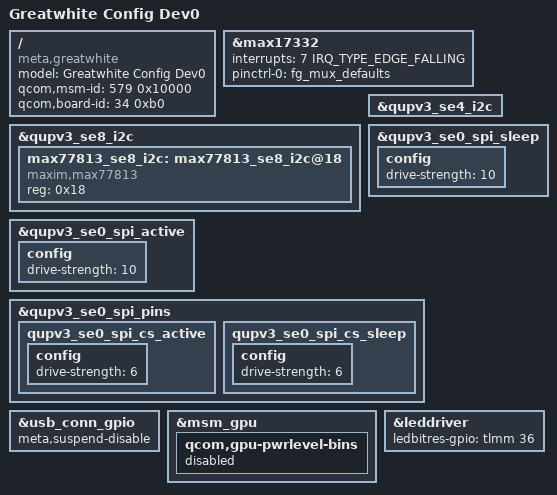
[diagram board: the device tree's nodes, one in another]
/dts-v1/;
/plugin/;

#include "greatwhite.dtsi"
#include "greatwhite-gpios.dtsi"

/ {
	model = "Greatwhite Config Dev0";
	compatible = "meta,greatwhite", "meta,greatwhite-dev0";
	qcom,msm-id = <579 0x10000>;
	qcom,board-id = <34 0xb0>;
};

&max17332 {
	interrupts = <7 IRQ_TYPE_EDGE_FALLING>;
	pinctrl-names = "default";
	pinctrl-0 = <&fg_mux_defaults>;
};

/delete-node/ &max77813;

&qupv3_se8_i2c {
	max77813_se8_i2c:max77813_se8_i2c@18 {
		compatible = "maxim,max77813";
		reg = <0x18>;
		status = "ok";
	};
};

/* Display card (Celeste) I2C bus: */

&qupv3_se4_i2c {
	status = "ok";
};


&qupv3_se0_spi_active {
	config {
		drive-strength = <10>;
	};
};

&qupv3_se0_spi_sleep {
	config {
		drive-strength = <10>;
	};
};

&qupv3_se0_spi_pins {
	qupv3_se0_spi_cs_active {
		config {
			drive-strength = <6>;
		};
	};

	qupv3_se0_spi_cs_sleep {
		config {
			drive-strength = <6>;
		};
	};
};

&usb_conn_gpio {
	meta,suspend-disable;
};

&msm_gpu {
	qcom,gpu-pwrlevel-bins {
		status = "disabled";
	};
};

&leddriver {
	ledbitres-gpio = <&tlmm 36 GPIO_ACTIVE_HIGH>;
};
